VERSION ""

NS_ :

BS_:

BU_:

BO_ 1 New_Message_2: 2 Vector__XXX
 SG_ New_Signal_1_Copy_4 : 8|8@1- (1,0) [0|0] "" Vector__XXX
 SG_ New_Signal_1_Copy_3 : 0|8@1- (1,0) [0|0] "" Vector__XXX

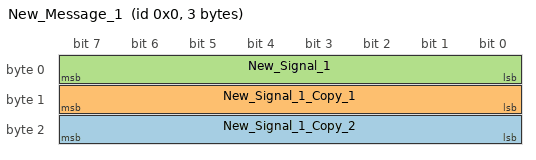
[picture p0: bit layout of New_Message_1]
BO_ 0 New_Message_1: 3 Vector__XXX
 SG_ New_Signal_1_Copy_2 : 16|8@1- (1,0) [0|0] "" Vector__XXX
 SG_ New_Signal_1_Copy_1 : 8|8@1- (1,0) [0|0] "" Vector__XXX
 SG_ New_Signal_1 : 0|8@1- (1,0) [0|0] "" Vector__XXX

BA_DEF_ BO_  "TxFreq" FLOAT 0 0;
BA_DEF_ BO_  "TypeFullBroadcast" INT 0 1;
BA_DEF_  "BusType" STRING ;
BA_DEF_DEF_  "TxFreq" 0;
BA_DEF_DEF_  "TypeFullBroadcast" 0;
BA_DEF_DEF_  "BusType" "CAN";
BA_ "TxFreq" BO_ 1 5;
BA_ "TxFreq" BO_ 0 0.017;
BA_ "TypeFullBroadcast" BO_ 0 1;
